# W7500x register map
Vendor: WIZnet; File version: 1.0.0
CPU: CM0 r0p0, little endian, no MPU, no FPU, 2 interrupt priority bits
Registers are 32-bit, read-write, reset 0x0 unless marked. A register's access mark holds for its fields unless they carry their own. Offsets are from the block's base; [hi:lo] are bit positions; {n}, {i} and the like mark numbered series; 'fields as' and 'values as' point back to an identical list.

## UART0
Base 0x4000C000
Same registers: UART1 0x4000D000
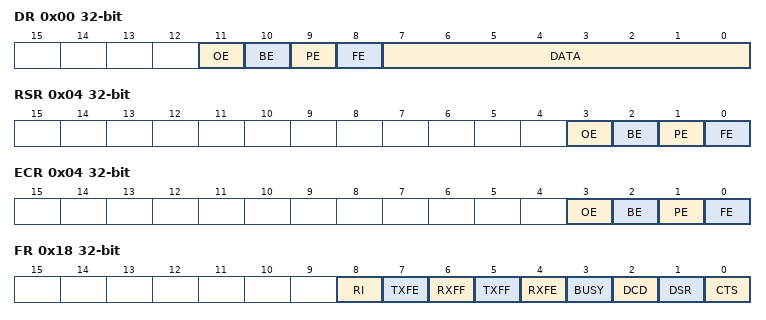
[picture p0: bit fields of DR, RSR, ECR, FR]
0x00 DR — Data
  [11] OE — Overrun Error
    1=FIFOFull
  [10] BE — Break Error
    1=Error (indicates that the received data input was held LOW of longer than a full word transmission time(defined as start, data, parity and stop bits))
  [9] PE — Parity Error
    1=Error (indicates that the parity of the received data character does not match the parity that the EPS and SPS bits in the line control register, UARTLCR_H select)
  [8] FE — Framing Error
    1=Error (indicates that the received character didn’t have a valid stop bit)
  [7:0] DATA — DATA[7:0] bits (Receive (READ)/Transmit (WRITE) data)
0x04 RSR ro — Receive Status
  [3] OE — Overrun Error
    1=FIFOFull
  [2] BE — Break Error
    values as DR.BE
  [1] PE — Parity Error
    values as DR.PE
  [0] FE — Framing Error
    values as DR.FE
0x04 ECR wo — Error Clear
  [all] fields
    1=Clear
  [3] OE — Overrun Error
  [2] BE — Break Error
  [1] PE — Parity Error
  [0] FE — Framing Error
0x18 FR ro reset not defined — Flags
  [8] RI — Ring indicator
    0=High; 1=Low
  [7] TXFE — Transmit FIFO empty
    0=TxHoldEmpty; 1=TxFIFOEmpty
  [6] RXFF — Receive FIFO full
    0=RxHoldFull; 1=RxFIFOFull
  [5] TXFF — Transmit FIFO fULl
    0=TxHoldFull; 1=TxFIFOFull
  [4] RXFE — Receive FIFO empty
    0=RxHoldEmpty; 1=RxFIFOEmpty
  [3] BUSY — UART busy
    1=Busy
  [2] DCD — Data carrier detect
    1=DataCarrierDetect
  [1] DSR — Data set ready
    1=DataSetReady
  [0] CTS — Clear to send
    1=ClearToSend
0x20 ILPR — IrDA Low-power Counter
  [7:0] ILPDVSR — low-power divisor value
0x24 IBRD reset not defined — Integer Baud Rate
0x28 FBRD reset not defined — Fractional Baud Rate
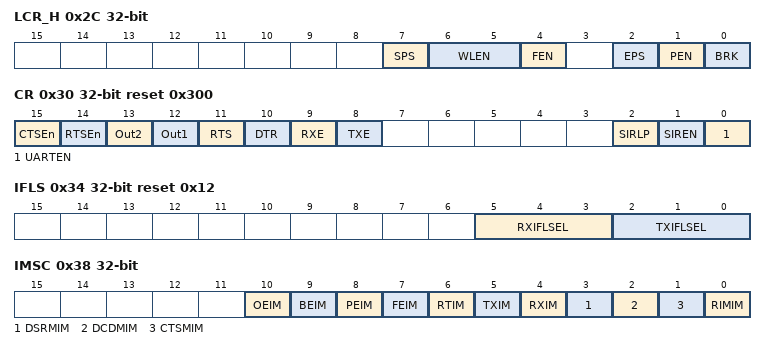
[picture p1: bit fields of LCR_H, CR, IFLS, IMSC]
0x2C LCR_H — Line Control
  [7] SPS — Stick parity select
    0=Disable; 1=Enable
  [6:5] WLEN — Word length
    {v}={v+5}Bits (v=0..3)
  [4] FEN — Enable FIFOs
    0=Disable; 1=Enable
  [2] EPS — Even parity select
    0=Odd; 1=Even
  [1] PEN — Parity enable
    0=Disable; 1=Enable
  [0] BRK — Send break
    0=Disable; 1=Enable
0x30 CR reset 0x300 — Control
  [15] CTSEn — CTS hardware flow control enable
    0=Disable; 1=Enable
  [14] RTSEn — RTS hardware flow control enable
    0=Disable; 1=Enable
  [13] Out2 — Complement of Out2 modem status output
    0=High; 1=Low
  [12] Out1 — Complement of Out1 modem status output
    0=High; 1=Low
  [11] RTS — Request to send
    0=High; 1=Low
  [10] DTR — Data transmit ready
    0=High; 1=Low
  [9] RXE — Receive enable
    0=Disable; 1=Enable
  [8] TXE — Transmit enable
    0=Disable; 1=Enable
  [2] SIRLP — IrDA SIR low power mode
    0=Disable (low level bits are transmitted as an active high pulse with a width of 3/16th of the bit period.); 1=Enable (low level bits are transmitted with a pulse width that is 3 times the period of the IrLPBaud16 input signal, regardless of the selected bit rate.)
  [1] SIREN — SIR enable
    0=Disable; 1=Enable
  [0] UARTEN — UART enable
    0=Disable; 1=Enable
0x34 IFLS reset 0x12 — Interrupt FIFO Level Select
  [5:3] RXIFLSEL — Receive interrupt FIFO level select
    0=Full1_8; 1=Full1_4; 2=Full1_2; 3=Full3_4; 4=Full7_8
  [2:0] TXIFLSEL — Transmit interrupt FIFO level select
    0=Full1_8; 1=Full1_4; 2=Full1_2; 3=Full3_4; 4=Full7_8
0x38 IMSC — Interrupt Mask Set / Clear
  [all] fields
    0=Disable; 1=Enable
  [10] OEIM — Overrun error interrupt mask
  [9] BEIM — Break error interrupt mask
  [8] PEIM — Parity error interrupt mask
  [7] FEIM — Framing error interrupt mask
  [6] RTIM — Receive interrupt mask
  [5] TXIM — Transmit interrupt mask
  [4] RXIM — Receive interrupt mask
  [3] DSRMIM — nUARTDSR modem interrupt mask
  [2] DCDMIM — nUARTDCD modem interrupt mask
  [1] CTSMIM — nUARTCTS modem interrupt mask
  [0] RIMIM — nUARTRI modem interrupt mask
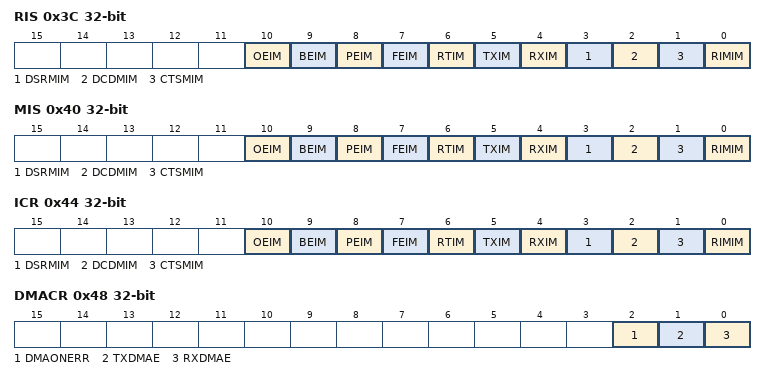
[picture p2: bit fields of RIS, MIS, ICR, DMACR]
0x3C RIS ro — Raw Interrupt Status
  [10] OEIM — Overrun error interrupt status
  [9] BEIM — Break error interrupt status
    1=Set
  [8] PEIM — Parity error interrupt status
    1=Set
  [7] FEIM — Framing error interrupt status
    1=Set
  [6] RTIM — Receive interrupt status
    1=Set
  [5] TXIM — Transmit interrupt status
    1=Set
  [4] RXIM — Receive interrupt status
    1=Set
  [3] DSRMIM — nUARTDSR modem interrupt status
    1=Set
  [2] DCDMIM — nUARTDCD modem interrupt status
    1=Set
  [1] CTSMIM — nUARTCTS modem interrupt status
    1=Set
  [0] RIMIM — nUARTRI modem interrupt status
    1=Set
0x40 MIS ro — Masked Interrupt Status
  [all] fields
    1=Set
  [10] OEIM — Overrun error masked interrupt status
  [9] BEIM — Break error masked interrupt status
  [8] PEIM — Parity error masked interrupt status
  [7] FEIM — Framing error masked interrupt status
  [6] RTIM — Receive masked interrupt status
  [5] TXIM — Transmit masked interrupt status
  [4] RXIM — Receive masked interrupt status
  [3] DSRMIM — nUARTDSR modem masked interrupt status
  [2] DCDMIM — nUARTDCD modem masked interrupt status
  [1] CTSMIM — nUARTCTS modem masked interrupt status
  [0] RIMIM — nUARTRI modem masked interrupt status
0x44 ICR wo — Interrupt Clear
  [all] fields
    1=Clear
  [10] OEIM — Overrun error interrupt clear
  [9] BEIM — Break error interrupt clear
  [8] PEIM — Parity error interrupt clear
  [7] FEIM — Framing error interrupt clear
  [6] RTIM — Receive interrupt clear
  [5] TXIM — Transmit interrupt clear
  [4] RXIM — Receive interrupt clear
  [3] DSRMIM — nUARTDSR modem interrupt clear
  [2] DCDMIM — nUARTDCD modem interrupt clear
  [1] CTSMIM — nUARTCTS modem interrupt clear
  [0] RIMIM — nUARTRI modem interrupt clear
0x48 DMACR — DMA Control
  [all] fields
    0=Disable; 1=Enable
  [2] DMAONERR — DMA on error
  [1] TXDMAE — Transmit DMA enable
  [0] RXDMAE — Receive DMA enable
